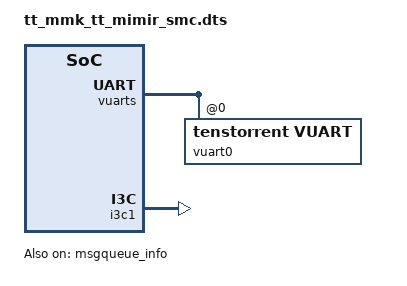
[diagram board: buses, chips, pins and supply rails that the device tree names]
/*
 * Copyright (c) 2026 Tenstorrent AI ULC
 *
 * SPDX-License-Identifier: Apache-2.0
 */

/dts-v1/;

#include <tenstorrent/tt_grendel_smc.dtsi>

/ {
	vuarts {
		#address-cells = <1>;
		#size-cells = <0>;

		vuart0: uart_tt_virt@0 {
			compatible = "tenstorrent,vuart";
			version = <0x00000000>;
			reg = <0x0>;
			status = "okay";
		};
	};

	chosen {
		zephyr,sram = &ram0;
		zephyr,console = &vuart0;
		zephyr,shell-uart = &vuart0;
	};

	msgqueue_mbox: msgqueue_mbox {
		compatible = "tenstorrent,msgqueue-mbox";
		mboxes = <&mbox0 1>;
		mbox-names = "doorbell";
		status = "okay";
	};
};

&i3c1 {
	status = "okay";
	input-clock-frequency = <1500000000>;
	i3c-scl-hz = <1000000>;
	i2c-scl-hz = <400000>;
};

&{/soc} {
	/* Cold Scratch 3 */
	msgqueue_info: scratch-reg@c000280c {
		compatible = "tenstorrent,scratch-reg";
		reg = <0x0 0xc000280c 0x0 0x4>;
		status = "okay";
	};
};
